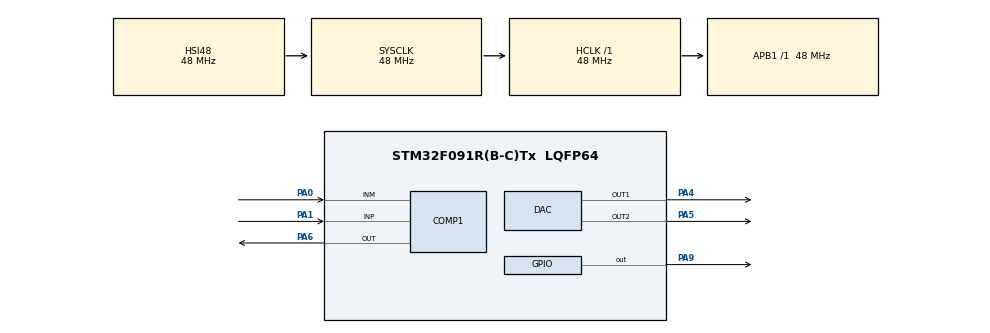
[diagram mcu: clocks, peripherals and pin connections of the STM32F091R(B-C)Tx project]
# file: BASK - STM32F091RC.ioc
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DAC.DAC_Trigger=DAC_TRIGGER_T2_TRGO
DAC.DAC_Trigger2=DAC_TRIGGER_T2_TRGO
Dma.DAC_CH1.0.Direction=DMA_MEMORY_TO_PERIPH
Dma.DAC_CH1.0.Instance=DMA1_Channel3
Dma.DAC_CH1.0.MemDataAlignment=DMA_MDATAALIGN_HALFWORD
Dma.DAC_CH1.0.MemInc=DMA_MINC_ENABLE
Dma.DAC_CH1.0.Mode=DMA_NORMAL
Dma.DAC_CH1.0.PeriphDataAlignment=DMA_PDATAALIGN_HALFWORD
Dma.DAC_CH1.0.PeriphInc=DMA_PINC_DISABLE
Dma.DAC_CH1.0.Priority=DMA_PRIORITY_LOW
Dma.DAC_CH2.1.Direction=DMA_MEMORY_TO_PERIPH
Dma.DAC_CH2.1.Instance=DMA1_Channel4
Dma.DAC_CH2.1.MemDataAlignment=DMA_MDATAALIGN_HALFWORD
Dma.DAC_CH2.1.MemInc=DMA_MINC_ENABLE
Dma.DAC_CH2.1.Mode=DMA_NORMAL
Dma.DAC_CH2.1.PeriphDataAlignment=DMA_PDATAALIGN_HALFWORD
Dma.DAC_CH2.1.PeriphInc=DMA_PINC_DISABLE
Dma.DAC_CH2.1.Priority=DMA_PRIORITY_LOW
Dma.Request0=DAC_CH1
Dma.Request1=DAC_CH2
Mcu.Family=STM32F0
Mcu.Name=STM32F091R(B-C)Tx
Mcu.Package=LQFP64
NVIC.DMA1_Ch2_3_DMA2_Ch1_2_IRQn=true\:0\:0\:false\:false\:true\:false\:true\:true
NVIC.DMA1_Ch4_7_DMA2_Ch3_5_IRQn=true\:0\:0\:false\:false\:true\:false\:true\:true
PA0.Mode=INM
PA0.Signal=COMP1_INM
PA1.Mode=INP
PA1.Signal=COMP1_INP
PA13.Mode=Serial_Wire
PA13.Signal=SYS_SWDIO
PA14.Mode=Serial_Wire
PA14.Signal=SYS_SWCLK
PA4.Signal=COMP_DAC1_group
PA5.Signal=COMP_DAC2_group
PA6.Mode=ExternalOutput
PA6.Signal=COMP1_OUT
PA9.Signal=GPIO_Output
ProjectManager.HeapSize=0x200
ProjectManager.StackSize=0x400
ProjectManager.TargetToolchain=MDK-ARM V5.32
RCC.AHBFreq_Value=48000000
RCC.APB1Freq_Value=48000000
RCC.APB1TimFreq_Value=48000000
RCC.HCLKFreq_Value=48000000
RCC.SYSCLKFreq_VALUE=48000000
RCC.SYSCLKSource=RCC_SYSCLKSOURCE_HSI48
SH.COMP_DAC1_group.0=DAC_OUT1,DAC_OUT1
SH.COMP_DAC2_group.0=DAC_OUT2,DAC_OUT2
TIM2.Period=99
TIM2.Prescaler=47
TIM2.TIM_MasterOutputTrigger=TIM_TRGO_UPDATE
VP_TIM2_VS_ClockSourceINT.Mode=Internal
board=custom

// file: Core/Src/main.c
/* USER CODE BEGIN Header */
/**
  ******************************************************************************
  * @file           : main.c
  * @brief          : Main program body
  ******************************************************************************
  * @attention
  *
  * Copyright (c) 2024 STMicroelectronics.
  * All rights reserved.
  *
  * This software is licensed under terms that can be found in the LICENSE file
  * in the root directory of this software component.
  * If no LICENSE file comes with this software, it is provided AS-IS.
  *
  ******************************************************************************
  */
/* USER CODE END Header */
#include "main.h"

/* USER CODE BEGIN Includes */
#include "telecommunication.h"
/* USER CODE END Includes */

COMP_HandleTypeDef hcomp1;

DAC_HandleTypeDef hdac;
DMA_HandleTypeDef hdma_dac_ch1;
DMA_HandleTypeDef hdma_dac_ch2;

TIM_HandleTypeDef htim2;

void SystemClock_Config(void);
static void MX_GPIO_Init(void);
static void MX_DMA_Init(void);
static void MX_DAC_Init(void);
static void MX_TIM2_Init(void);
static void MX_COMP1_Init(void);

int main(void)
{

  /* MCU Configuration--------------------------------------------------------*/

  /* Reset of all peripherals, Initializes the Flash interface and the Systick. */
  HAL_Init();

  /* Configure the system clock */
  SystemClock_Config();

  /* Initialize all configured peripherals */
  MX_GPIO_Init();
  MX_DMA_Init();
  MX_DAC_Init();
  MX_TIM2_Init();
  MX_COMP1_Init();
  /* USER CODE BEGIN 2 */
	mainCode();
  /* USER CODE END 2 */

  /* Infinite loop */
  while (1)
  {

  }
}

void SystemClock_Config(void)
{
  RCC_OscInitTypeDef RCC_OscInitStruct = {0};
  RCC_ClkInitTypeDef RCC_ClkInitStruct = {0};

  /** Initializes the RCC Oscillators according to the specified parameters
  * in the RCC_OscInitTypeDef structure.
  */
  RCC_OscInitStruct.OscillatorType = RCC_OSCILLATORTYPE_HSI48;
  RCC_OscInitStruct.HSI48State = RCC_HSI48_ON;
  RCC_OscInitStruct.PLL.PLLState = RCC_PLL_NONE;
  if (HAL_RCC_OscConfig(&RCC_OscInitStruct) != HAL_OK)
  {
    Error_Handler();
  }

  /** Initializes the CPU, AHB and APB buses clocks
  */
  RCC_ClkInitStruct.ClockType = RCC_CLOCKTYPE_HCLK|RCC_CLOCKTYPE_SYSCLK
                              |RCC_CLOCKTYPE_PCLK1;
  RCC_ClkInitStruct.SYSCLKSource = RCC_SYSCLKSOURCE_HSI48;
  RCC_ClkInitStruct.AHBCLKDivider = RCC_SYSCLK_DIV1;
  RCC_ClkInitStruct.APB1CLKDivider = RCC_HCLK_DIV1;

  if (HAL_RCC_ClockConfig(&RCC_ClkInitStruct, FLASH_LATENCY_1) != HAL_OK)
  {
    Error_Handler();
  }
}

static void MX_COMP1_Init(void)
{

  hcomp1.Instance = COMP1;
  hcomp1.Init.InvertingInput = COMP_INVERTINGINPUT_IO1;
  hcomp1.Init.NonInvertingInput = COMP_NONINVERTINGINPUT_IO1;
  hcomp1.Init.Output = COMP_OUTPUT_NONE;
  hcomp1.Init.OutputPol = COMP_OUTPUTPOL_NONINVERTED;
  hcomp1.Init.Hysteresis = COMP_HYSTERESIS_NONE;
  hcomp1.Init.Mode = COMP_MODE_HIGHSPEED;
  hcomp1.Init.WindowMode = COMP_WINDOWMODE_DISABLE;
  hcomp1.Init.TriggerMode = COMP_TRIGGERMODE_NONE;
  if (HAL_COMP_Init(&hcomp1) != HAL_OK)
  {
    Error_Handler();
  }

}

static void MX_DAC_Init(void)
{

  DAC_ChannelConfTypeDef sConfig = {0};

  /** DAC Initialization
  */
  hdac.Instance = DAC;
  if (HAL_DAC_Init(&hdac) != HAL_OK)
  {
    Error_Handler();
  }

  /** DAC channel OUT1 config
  */
  sConfig.DAC_Trigger = DAC_TRIGGER_T2_TRGO;
  sConfig.DAC_OutputBuffer = DAC_OUTPUTBUFFER_ENABLE;
  if (HAL_DAC_ConfigChannel(&hdac, &sConfig, DAC_CHANNEL_1) != HAL_OK)
  {
    Error_Handler();
  }

  /** DAC channel OUT2 config
  */
  if (HAL_DAC_ConfigChannel(&hdac, &sConfig, DAC_CHANNEL_2) != HAL_OK)
  {
    Error_Handler();
  }

}

static void MX_TIM2_Init(void)
{

  TIM_ClockConfigTypeDef sClockSourceConfig = {0};
  TIM_MasterConfigTypeDef sMasterConfig = {0};

  htim2.Instance = TIM2;
  htim2.Init.Prescaler = 47;
  htim2.Init.CounterMode = TIM_COUNTERMODE_UP;
  htim2.Init.Period = 99;
  htim2.Init.ClockDivision = TIM_CLOCKDIVISION_DIV1;
  htim2.Init.AutoReloadPreload = TIM_AUTORELOAD_PRELOAD_DISABLE;
  if (HAL_TIM_Base_Init(&htim2) != HAL_OK)
  {
    Error_Handler();
  }
  sClockSourceConfig.ClockSource = TIM_CLOCKSOURCE_INTERNAL;
  if (HAL_TIM_ConfigClockSource(&htim2, &sClockSourceConfig) != HAL_OK)
  {
    Error_Handler();
  }
  sMasterConfig.MasterOutputTrigger = TIM_TRGO_UPDATE;
  sMasterConfig.MasterSlaveMode = TIM_MASTERSLAVEMODE_DISABLE;
  if (HAL_TIMEx_MasterConfigSynchronization(&htim2, &sMasterConfig) != HAL_OK)
  {
    Error_Handler();
  }

}

static void MX_DMA_Init(void)
{

  /* DMA controller clock enable */
  __HAL_RCC_DMA1_CLK_ENABLE();

  /* DMA interrupt init */
  /* DMA1_Ch2_3_DMA2_Ch1_2_IRQn interrupt configuration */
  HAL_NVIC_SetPriority(DMA1_Ch2_3_DMA2_Ch1_2_IRQn, 0, 0);
  HAL_NVIC_EnableIRQ(DMA1_Ch2_3_DMA2_Ch1_2_IRQn);
  /* DMA1_Ch4_7_DMA2_Ch3_5_IRQn interrupt configuration */
  HAL_NVIC_SetPriority(DMA1_Ch4_7_DMA2_Ch3_5_IRQn, 0, 0);
  HAL_NVIC_EnableIRQ(DMA1_Ch4_7_DMA2_Ch3_5_IRQn);

}

static void MX_GPIO_Init(void)
{
  GPIO_InitTypeDef GPIO_InitStruct = {0};

  /* GPIO Ports Clock Enable */
  __HAL_RCC_GPIOA_CLK_ENABLE();

  /*Configure GPIO pin Output Level */
  HAL_GPIO_WritePin(GPIOA, GPIO_PIN_9, GPIO_PIN_RESET);

  /*Configure GPIO pin : PA9 */
  GPIO_InitStruct.Pin = GPIO_PIN_9;
  GPIO_InitStruct.Mode = GPIO_MODE_OUTPUT_PP;
  GPIO_InitStruct.Pull = GPIO_NOPULL;
  GPIO_InitStruct.Speed = GPIO_SPEED_FREQ_LOW;
  HAL_GPIO_Init(GPIOA, &GPIO_InitStruct);

}

void Error_Handler(void)
{
  __disable_irq();
  while (1)
  {
  }
}
